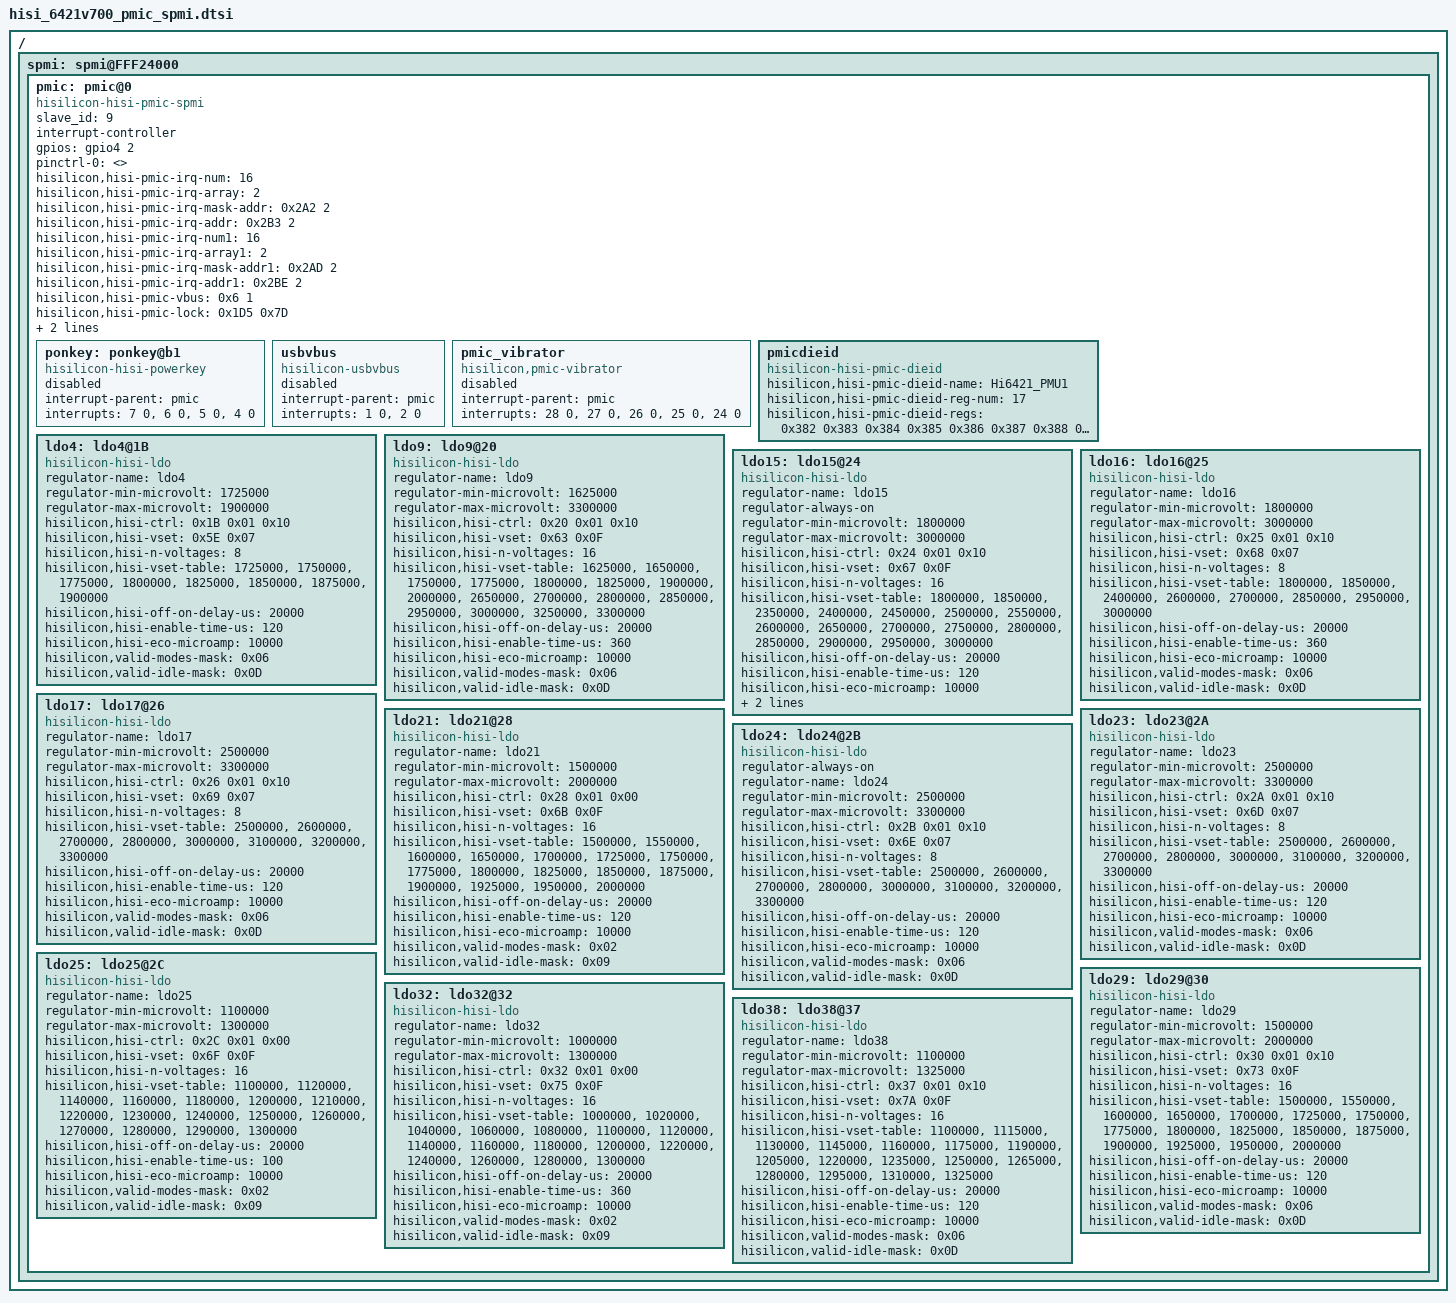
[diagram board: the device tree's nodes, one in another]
/*
 *  Copyright (C) 2012-2013 Linaro Ltd.
 *
 *  This program is free software; you can redistribute it and/or modify
 *  it under the terms of the GNU General Public License version 2 as
 *  publishhed by the Free Software Foundation.
 */
 /*hisilicon,valid-modes-mask:
*#define REGULATOR_MODE_FAST                     0x1
*#define REGULATOR_MODE_NORMAL                   0x2
*#define REGULATOR_MODE_IDLE                     0x4
*#define REGULATOR_MODE_STANDBY                  0x8
*/
/*hisilicon,valid-idle-mask:
*#define REGULATOR_CHANGE_VOLTAGE        0x1
*#define REGULATOR_CHANGE_CURRENT        0x2
*#define REGULATOR_CHANGE_MODE           0x4
*#define REGULATOR_CHANGE_STATUS         0x8
*#define REGULATOR_CHANGE_DRMS           0x10
*#define REGULATOR_CHANGE_BYPASS         0x20
*/
/ {
	spmi: spmi@FFF24000 {
		pmic: pmic@0 {
			compatible = "hisilicon-hisi-pmic-spmi";
			slave_id = <9>;
			#interrupt-cells = <2>;
			interrupt-controller;
			gpios = <&gpio4 2 0>;
			pinctrl-names = "default";
			pinctrl-0 = <>;
			hisilicon,hisi-pmic-irq-num = <16>;/*hisi irq number*/
			hisilicon,hisi-pmic-irq-array = <2>;/*hisi irq array*/
			hisilicon,hisi-pmic-irq-mask-addr = <0x2A2 2>;/*hisi irq mask addr*/
			hisilicon,hisi-pmic-irq-addr = <0x2B3 2>;/*hisi irq addr*/
			/*for ext-interrupts int the hi6421v700*/
			hisilicon,hisi-pmic-irq-num1 = <16>;/*hisi irq number*/
			hisilicon,hisi-pmic-irq-array1 = <2>;/*hisi irq array*/
			hisilicon,hisi-pmic-irq-mask-addr1 = <0x2AD 2>;/*hisi irq mask addr*/
			hisilicon,hisi-pmic-irq-addr1 = <0x2BE 2>;/*hisi irq addr*/
			hisilicon,hisi-pmic-vbus = <0x6 1>;/*vbus status addr and bit*/
			hisilicon,hisi-pmic-lock = <0x1D5 0x7D>; /*lock: <addr value>*/
			hisilicon,hisi-pmic-debug-lock = <0x2EB 0x6C>;/*debug-lock: <addr value>*/
			spmi-slave-container;/*spmi-dev-container;*/

			ponkey:ponkey@b1{
					compatible = "hisilicon-hisi-powerkey";
					interrupt-parent = <&pmic>;
					interrupts = <7 0>, <6 0>, <5 0>, <4 0>;
					interrupt-names = "down", "up", "hold 1s", "hold 6s";
					status = "disabled";
			};

			usbvbus {
				compatible = "hisilicon-usbvbus";
				interrupt-parent = <&pmic>;
				interrupts = <1 0>, <2 0>;
				interrupt-names = "connect", "disconnect";
				status = "disabled";
			};

			pmic_vibrator {
				compatible = "hisilicon,pmic-vibrator";
				interrupt-parent = <&pmic>;
				interrupts =<28 0>, <27 0>, <26 0>, <25 0>, <24 0>;
				interrupt-names = "adc", "overvol", "undervol", "out", "ocp";
				status = "disabled";
			};

			pmicdieid {
				compatible = "hisilicon-hisi-pmic-dieid";
				hisilicon,hisi-pmic-dieid-name = "Hi6421_PMU1"; /*dieid: <chip name>*/
				hisilicon,hisi-pmic-dieid-reg-num = <17>; /*dieid: <register number>*/
				hisilicon,hisi-pmic-dieid-regs = <0x382 0x383 0x384 0x385 0x386 0x387 0x388 0x389 0x38A 0x38B 0x38C 0x38D 0x38E 0x38F 0x390 0x391 0x392>; /*dieid: <addr value>*/
			};

			ldo4: ldo4@1B {
				compatible = "hisilicon-hisi-ldo";
				regulator-name = "ldo4";
				regulator-min-microvolt = <1725000>;
				regulator-max-microvolt = <1900000>;
				hisilicon,hisi-ctrl = <0x1B 0x01 0x10>;/*ctrl_reg、enable_mask、eco_mode_mask*/
				hisilicon,hisi-vset = <0x5E 0x07>;
				hisilicon,hisi-n-voltages = <8>;
				hisilicon,hisi-vset-table = <1725000>, <1750000>,
											<1775000>, <1800000>,
											<1825000>, <1850000>,
											<1875000>, <1900000>;
				hisilicon,hisi-off-on-delay-us = <20000>;
				hisilicon,hisi-enable-time-us = <120>;
				hisilicon,hisi-eco-microamp = <10000>;
				hisilicon,valid-modes-mask = <0x06>;
				hisilicon,valid-idle-mask = <0x0D>;
			};

			ldo9: ldo9@20 {
				compatible = "hisilicon-hisi-ldo";
				regulator-name = "ldo9";
				regulator-min-microvolt = <1625000>;
				regulator-max-microvolt = <3300000>;
				hisilicon,hisi-ctrl = <0x20 0x01 0x10>;
				hisilicon,hisi-vset = <0x63 0x0F>;
				hisilicon,hisi-n-voltages = <16>;
				hisilicon,hisi-vset-table = <1625000>, <1650000>,
											<1750000>, <1775000>,
											<1800000>, <1825000>,
											<1900000>, <2000000>,
											<2650000>, <2700000>,
											<2800000>, <2850000>,
											<2950000>, <3000000>,
											<3250000>, <3300000>;
				hisilicon,hisi-off-on-delay-us = <20000>;
				hisilicon,hisi-enable-time-us = <360>;
				hisilicon,hisi-eco-microamp = <10000>;
				hisilicon,valid-modes-mask = <0x06>;
				hisilicon,valid-idle-mask = <0x0D>;
			};

			ldo15: ldo15@24 {
				compatible = "hisilicon-hisi-ldo";
				regulator-name = "ldo15";
				regulator-always-on;
				regulator-min-microvolt = <1800000>;
				regulator-max-microvolt = <3000000>;
				hisilicon,hisi-ctrl = <0x24 0x01 0x10>;
				hisilicon,hisi-vset = <0x67 0x0F>;
				hisilicon,hisi-n-voltages = <16>;
				hisilicon,hisi-vset-table = <1800000>, <1850000>,
											<2350000>, <2400000>,
											<2450000>, <2500000>,
											<2550000>, <2600000>,
											<2650000>, <2700000>,
											<2750000>, <2800000>,
											<2850000>, <2900000>,
											<2950000>, <3000000>;
				hisilicon,hisi-off-on-delay-us = <20000>;
				hisilicon,hisi-enable-time-us = <120>;
				hisilicon,hisi-eco-microamp = <10000>;
				hisilicon,valid-modes-mask = <0x06>;
				hisilicon,valid-idle-mask = <0x0D>;
			};

			ldo16: ldo16@25 {
				compatible = "hisilicon-hisi-ldo";
				regulator-name = "ldo16";
				regulator-min-microvolt = <1800000>;
				regulator-max-microvolt = <3000000>;
				hisilicon,hisi-ctrl = <0x25 0x01 0x10>;
				hisilicon,hisi-vset = <0x68 0x07>;
				hisilicon,hisi-n-voltages = <8>;
				hisilicon,hisi-vset-table = <1800000>, <1850000>,
											<2400000>, <2600000>,
											<2700000>, <2850000>,
											<2950000>, <3000000>;
				hisilicon,hisi-off-on-delay-us = <20000>;
				hisilicon,hisi-enable-time-us = <360>;
				hisilicon,hisi-eco-microamp = <10000>;
				hisilicon,valid-modes-mask = <0x06>;
				hisilicon,valid-idle-mask = <0x0D>;
			};

			ldo17: ldo17@26 {
				compatible = "hisilicon-hisi-ldo";
				regulator-name = "ldo17";
				regulator-min-microvolt = <2500000>;
				regulator-max-microvolt = <3300000>;
				hisilicon,hisi-ctrl = <0x26 0x01 0x10>;
				hisilicon,hisi-vset = <0x69 0x07>;
				hisilicon,hisi-n-voltages = <8>;
				hisilicon,hisi-vset-table = <2500000>, <2600000>,
											<2700000>, <2800000>,
											<3000000>, <3100000>,
											<3200000>, <3300000>;
				hisilicon,hisi-off-on-delay-us = <20000>;
				hisilicon,hisi-enable-time-us = <120>;
				hisilicon,hisi-eco-microamp = <10000>;
				hisilicon,valid-modes-mask = <0x06>;
				hisilicon,valid-idle-mask = <0x0D>;
			};

			ldo21: ldo21@28 {
				compatible = "hisilicon-hisi-ldo";
				regulator-name = "ldo21";
				regulator-min-microvolt = <1500000>;
				regulator-max-microvolt = <2000000>;
				hisilicon,hisi-ctrl = <0x28 0x01 0x00>;
				hisilicon,hisi-vset = <0x6B 0x0F>;
				hisilicon,hisi-n-voltages = <16>;
				hisilicon,hisi-vset-table =  <1500000>,  <1550000>,
											<1600000>,  <1650000>,
											<1700000>, <1725000>,
											<1750000>, <1775000>,
											<1800000>, <1825000>,
											<1850000>, <1875000>,
											<1900000>, <1925000>,
											<1950000>, <2000000>;
				hisilicon,hisi-off-on-delay-us = <20000>;
				hisilicon,hisi-enable-time-us = <120>;
				hisilicon,hisi-eco-microamp = <10000>;
				hisilicon,valid-modes-mask = <0x02>;
				hisilicon,valid-idle-mask = <0x09>;
			};

			ldo23: ldo23@2A {
				compatible = "hisilicon-hisi-ldo";
				regulator-name = "ldo23";
				regulator-min-microvolt = <2500000>;
				regulator-max-microvolt = <3300000>;
				hisilicon,hisi-ctrl = <0x2A 0x01 0x10>;
				hisilicon,hisi-vset = <0x6D 0x07>;
				hisilicon,hisi-n-voltages = <8>;
				hisilicon,hisi-vset-table = <2500000>, <2600000>,
											<2700000>, <2800000>,
											<3000000>, <3100000>,
											<3200000>, <3300000>;
				hisilicon,hisi-off-on-delay-us = <20000>;
				hisilicon,hisi-enable-time-us = <120>;
				hisilicon,hisi-eco-microamp = <10000>;
				hisilicon,valid-modes-mask = <0x06>;
				hisilicon,valid-idle-mask = <0x0D>;
			};

			ldo24: ldo24@2B {
				compatible = "hisilicon-hisi-ldo";
				regulator-always-on;
				regulator-name = "ldo24";
				regulator-min-microvolt = <2500000>;
				regulator-max-microvolt = <3300000>;
				hisilicon,hisi-ctrl = <0x2B 0x01 0x10>;
				hisilicon,hisi-vset = <0x6E 0x07>;
				hisilicon,hisi-n-voltages = <8>;
				hisilicon,hisi-vset-table = <2500000>, <2600000>,
											<2700000>, <2800000>,
											<3000000>, <3100000>,
											<3200000>, <3300000>;
				hisilicon,hisi-off-on-delay-us = <20000>;
				hisilicon,hisi-enable-time-us = <120>;
				hisilicon,hisi-eco-microamp = <10000>;
				hisilicon,valid-modes-mask = <0x06>;
				hisilicon,valid-idle-mask = <0x0D>;
			};


			ldo25: ldo25@2C {
				compatible = "hisilicon-hisi-ldo";
				regulator-name = "ldo25";
				regulator-min-microvolt = <1100000>;
				regulator-max-microvolt = <1300000>;
				hisilicon,hisi-ctrl = <0x2C 0x01 0x00>;
				hisilicon,hisi-vset = <0x6F 0x0F>;
				hisilicon,hisi-n-voltages = <16>;
				hisilicon,hisi-vset-table = <1100000>, <1120000>,
											<1140000>, <1160000>,
											<1180000>, <1200000>,
											<1210000>, <1220000>,
											<1230000>, <1240000>,
											<1250000>, <1260000>,
											<1270000>, <1280000>,
											<1290000>, <1300000>;
				hisilicon,hisi-off-on-delay-us = <20000>;
				hisilicon,hisi-enable-time-us = <100>;
				hisilicon,hisi-eco-microamp = <10000>;
				hisilicon,valid-modes-mask = <0x02>;
				hisilicon,valid-idle-mask = <0x09>;
			};

			ldo29: ldo29@30 {
				compatible = "hisilicon-hisi-ldo";
				regulator-name = "ldo29";
				regulator-min-microvolt = <1500000>;
				regulator-max-microvolt = <2000000>;
				hisilicon,hisi-ctrl = <0x30 0x01 0x10>;
				hisilicon,hisi-vset = <0x73 0x0F>;
				hisilicon,hisi-n-voltages = <16>;
				hisilicon,hisi-vset-table = <1500000>, <1550000>,
											<1600000>, <1650000>,
											<1700000>, <1725000>,
											<1750000>, <1775000>,
											<1800000>, <1825000>,
											<1850000>, <1875000>,
											<1900000>, <1925000>,
											<1950000>, <2000000>;
				hisilicon,hisi-off-on-delay-us = <20000>;
				hisilicon,hisi-enable-time-us = <120>;
				hisilicon,hisi-eco-microamp = <10000>;
				hisilicon,valid-modes-mask = <0x06>;
				hisilicon,valid-idle-mask = <0x0D>;
			};

			ldo32: ldo32@32 {
				compatible = "hisilicon-hisi-ldo";
				regulator-name = "ldo32";
				regulator-min-microvolt = <1000000>;
				regulator-max-microvolt = <1300000>;
				hisilicon,hisi-ctrl = <0x32 0x01 0x00>;
				hisilicon,hisi-vset = <0x75 0x0F>;
				hisilicon,hisi-n-voltages = <16>;
				hisilicon,hisi-vset-table = <1000000>,  <1020000>,
											<1040000>, <1060000>,
											<1080000>, <1100000>,
											<1120000>, <1140000>,
											<1160000>, <1180000>,
											<1200000>, <1220000>,
											<1240000>, <1260000>,
											<1280000>, <1300000>;
				hisilicon,hisi-off-on-delay-us = <20000>;
				hisilicon,hisi-enable-time-us = <360>;
				hisilicon,hisi-eco-microamp = <10000>;
				hisilicon,valid-modes-mask = <0x02>;
				hisilicon,valid-idle-mask = <0x09>;
			};

			ldo38: ldo38@37 {
				compatible = "hisilicon-hisi-ldo";
				regulator-name = "ldo38";
				regulator-min-microvolt = <1100000>;
				regulator-max-microvolt = <1325000>;
				hisilicon,hisi-ctrl = <0x37 0x01 0x10>;
				hisilicon,hisi-vset = <0x7A 0x0F>;
				hisilicon,hisi-n-voltages = <16>;
				hisilicon,hisi-vset-table = <1100000>, <1115000>,
											<1130000>, <1145000>,
											<1160000>, <1175000>,
											<1190000>, <1205000>,
											<1220000>, <1235000>,
											<1250000>, <1265000>,
											<1280000>, <1295000>,
											<1310000>, <1325000>;
				hisilicon,hisi-off-on-delay-us = <20000>;
				hisilicon,hisi-enable-time-us = <120>;
				hisilicon,hisi-eco-microamp = <10000>;
				hisilicon,valid-modes-mask = <0x06>;
				hisilicon,valid-idle-mask = <0x0D>;
			};
		};/* end of pmic */
	};/*end of spmi*/
};
